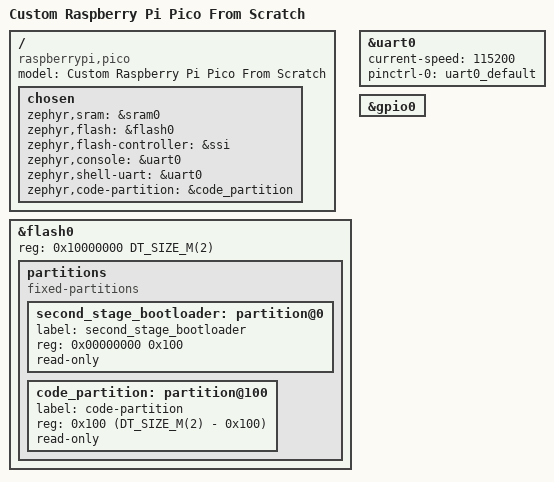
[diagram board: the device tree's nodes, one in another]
/dts-v1/;
#include <mem.h>
#include <raspberrypi/rpi_pico/rp2040.dtsi>
#include "custom_pico_scratch-pinctrl.dtsi"

/ {
	model = "Custom Raspberry Pi Pico From Scratch";
	compatible = "raspberrypi,pico";

	chosen {
		zephyr,sram = &sram0;
		zephyr,flash = &flash0;
		zephyr,flash-controller = &ssi;
		zephyr,console = &uart0;
		zephyr,shell-uart = &uart0;
		zephyr,code-partition = &code_partition;
	};
};
	&flash0 {
	reg = <0x10000000 DT_SIZE_M(2)>;

	partitions {
		compatible = "fixed-partitions";
		#address-cells = <1>;
		#size-cells = <1>;

		second_stage_bootloader: partition@0 {
			label = "second_stage_bootloader";
			reg = <0x00000000 0x100>;
			read-only;
		};

		code_partition: partition@100 {
			label = "code-partition";
			reg = <0x100 (DT_SIZE_M(2) - 0x100)>;
			read-only;
		};
	};
};

&uart0 {
	current-speed = <115200>;
	status = "okay";
	pinctrl-0 = <&uart0_default>;
	pinctrl-names = "default";
};

&gpio0 {
	status = "okay";
};
